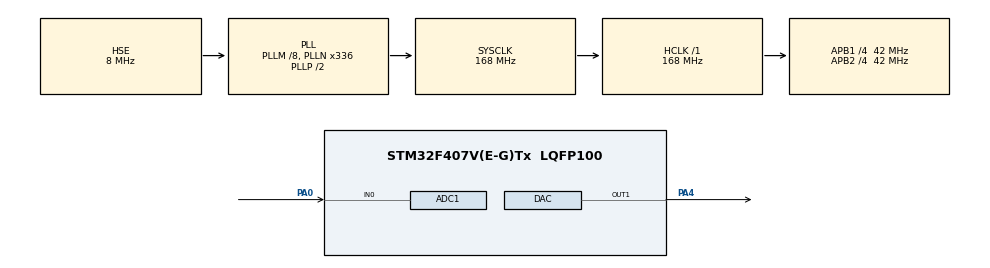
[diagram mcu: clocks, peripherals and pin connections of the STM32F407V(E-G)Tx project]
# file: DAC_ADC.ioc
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ADC1.Channel-0\#ChannelRegularConversion=ADC_CHANNEL_0
ADC1.ContinuousConvMode=ENABLE
ADC1.NbrOfConversionFlag=1
ADC1.Rank-0\#ChannelRegularConversion=1
ADC1.SamplingTime-0\#ChannelRegularConversion=ADC_SAMPLETIME_480CYCLES
ADC1.master=1
Mcu.Family=STM32F4
Mcu.Name=STM32F407V(E-G)Tx
Mcu.Package=LQFP100
NVIC.ADC_IRQn=true\:0\:0\:false\:false\:true
NVIC.PriorityGroup=NVIC_PRIORITYGROUP_4
PA0-WKUP.Signal=ADCx_IN0
PA4.Signal=COMP_DAC1_group
PH0-OSC_IN.Mode=HSE-External-Oscillator
PH0-OSC_IN.Signal=RCC_OSC_IN
PH1-OSC_OUT.Mode=HSE-External-Oscillator
PH1-OSC_OUT.Signal=RCC_OSC_OUT
ProjectManager.HeapSize=0x200
ProjectManager.StackSize=0x400
ProjectManager.TargetToolchain=MDK-ARM V5
RCC.48MHZClocksFreq_Value=84000000
RCC.AHBFreq_Value=168000000
RCC.APB1CLKDivider=RCC_HCLK_DIV4
RCC.APB1Freq_Value=42000000
RCC.APB1TimFreq_Value=84000000
RCC.APB2CLKDivider=RCC_HCLK_DIV4
RCC.APB2Freq_Value=42000000
RCC.APB2TimFreq_Value=84000000
RCC.CortexFreq_Value=168000000
RCC.HCLKFreq_Value=168000000
RCC.HSE_VALUE=8000000
RCC.HSI_VALUE=16000000
RCC.LSE_VALUE=32768
RCC.PLLM=8
RCC.PLLN=336
RCC.PLLSourceVirtual=RCC_PLLSOURCE_HSE
RCC.SYSCLKFreq_VALUE=168000000
RCC.SYSCLKSource=RCC_SYSCLKSOURCE_PLLCLK
RCC.VCOOutputFreq_Value=336000000
SH.ADCx_IN0.0=ADC1_IN0,IN0
SH.COMP_DAC1_group.0=DAC_OUT1,DAC_OUT1
board=DAC_ADC

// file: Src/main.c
/**
  ******************************************************************************
  * File Name          : main.c
  * Description        : Main program body
  ******************************************************************************
  *
  * COPYRIGHT(c) 2016 STMicroelectronics
  *
  * Redistribution and use in source and binary forms, with or without modification,
  * are permitted provided that the following conditions are met:
  *   1. Redistributions of source code must retain the above copyright notice,
  *      this list of conditions and the following disclaimer.
  *   2. Redistributions in binary form must reproduce the above copyright notice,
  *      this list of conditions and the following disclaimer in the documentation
  *      and/or other materials provided with the distribution.
  *   3. Neither the name of STMicroelectronics nor the names of its contributors
  *      may be used to endorse or promote products derived from this software
  *      without specific prior written permission.
  *
  * THIS SOFTWARE IS PROVIDED BY THE COPYRIGHT HOLDERS AND CONTRIBUTORS "AS IS"
  * AND ANY EXPRESS OR IMPLIED WARRANTIES, INCLUDING, BUT NOT LIMITED TO, THE
  * IMPLIED WARRANTIES OF MERCHANTABILITY AND FITNESS FOR A PARTICULAR PURPOSE ARE
  * DISCLAIMED. IN NO EVENT SHALL THE COPYRIGHT HOLDER OR CONTRIBUTORS BE LIABLE
  * FOR ANY DIRECT, INDIRECT, INCIDENTAL, SPECIAL, EXEMPLARY, OR CONSEQUENTIAL
  * DAMAGES (INCLUDING, BUT NOT LIMITED TO, PROCUREMENT OF SUBSTITUTE GOODS OR
  * SERVICES; LOSS OF USE, DATA, OR PROFITS; OR BUSINESS INTERRUPTION) HOWEVER
  * CAUSED AND ON ANY THEORY OF LIABILITY, WHETHER IN CONTRACT, STRICT LIABILITY,
  * OR TORT (INCLUDING NEGLIGENCE OR OTHERWISE) ARISING IN ANY WAY OUT OF THE USE
  * OF THIS SOFTWARE, EVEN IF ADVISED OF THE POSSIBILITY OF SUCH DAMAGE.
  *
  ******************************************************************************
  */
#include "stm32f4xx_hal.h"

/* USER CODE BEGIN Includes */

/* Mo ta hoat dong:
 * Chuong trinh thuc hien xuat ra gia tri dien ap tuong tu (DAC)tren chan PA4
 * Sau khoang thoi gian la 2S thi gia tri dien ap tang them 0.2V.
 * Sau do chuong trinh se thuc hien qua trinh chuyen doi tuong tu so (ADC) tren
 * chan PA0 va tinh toan gia tri dien ap. De kiem tra xem qua trinh DAC co dung
 * nhu mong muon khong, thi ta se noi day cha PA0 va chan PA4 .
 *
 * Ket noi phan cung:
 * Chan PA0 noi voi chan PA4
 */

/* USER CODE END Includes */

ADC_HandleTypeDef hadc1;

DAC_HandleTypeDef hdac;

/* USER CODE BEGIN PV */
/* Private variables ---------------------------------------------------------*/
uint16_t adc_value;
float theory_voltage=0,real_voltage=0;
/* USER CODE END PV */

void SystemClock_Config(void);
void Error_Handler(void);
static void MX_GPIO_Init(void);
static void MX_ADC1_Init(void);
static void MX_DAC_Init(void);

/* USER CODE BEGIN PFP */
/* Private function prototypes -----------------------------------------------*/

/* USER CODE END PFP */

int main(void)
{

  /* MCU Configuration----------------------------------------------------------*/

  /* Reset of all peripherals, Initializes the Flash interface and the Systick. */
  HAL_Init();
  /* Configure the system clock */
  SystemClock_Config();

  /* Initialize all configured peripherals */
  MX_GPIO_Init();
  MX_ADC1_Init();
  MX_DAC_Init();

  /* USER CODE BEGIN 2 */
	HAL_ADC_Start_IT(&hadc1);
	HAL_DAC_Start(&hdac,DAC_CHANNEL_1);
  /* USER CODE END 2 */

  /* Infinite loop */
  while (1)
  {
  /* USER CODE BEGIN 3 */
		HAL_DAC_SetValue(&hdac,DAC_CHANNEL_1,DAC_ALIGN_12B_R,(uint32_t)((theory_voltage/(float)3.0)*(float)4095.0));

		HAL_Delay(2000);

		theory_voltage+=(float)0.20;
		if(theory_voltage>(float)3.1)
		{
			theory_voltage=0;
		}
  }
  /* USER CODE END 3 */

}

/** System Clock Configuration
*/
void SystemClock_Config(void)
{

  RCC_OscInitTypeDef RCC_OscInitStruct;
  RCC_ClkInitTypeDef RCC_ClkInitStruct;

  __HAL_RCC_PWR_CLK_ENABLE();

  __HAL_PWR_VOLTAGESCALING_CONFIG(PWR_REGULATOR_VOLTAGE_SCALE1);

  RCC_OscInitStruct.OscillatorType = RCC_OSCILLATORTYPE_HSE;
  RCC_OscInitStruct.HSEState = RCC_HSE_ON;
  RCC_OscInitStruct.PLL.PLLState = RCC_PLL_ON;
  RCC_OscInitStruct.PLL.PLLSource = RCC_PLLSOURCE_HSE;
  RCC_OscInitStruct.PLL.PLLM = 8;
  RCC_OscInitStruct.PLL.PLLN = 336;
  RCC_OscInitStruct.PLL.PLLP = RCC_PLLP_DIV2;
  RCC_OscInitStruct.PLL.PLLQ = 4;
  if (HAL_RCC_OscConfig(&RCC_OscInitStruct) != HAL_OK)
  {
    Error_Handler();
  }

  RCC_ClkInitStruct.ClockType = RCC_CLOCKTYPE_HCLK|RCC_CLOCKTYPE_SYSCLK
                              |RCC_CLOCKTYPE_PCLK1|RCC_CLOCKTYPE_PCLK2;
  RCC_ClkInitStruct.SYSCLKSource = RCC_SYSCLKSOURCE_PLLCLK;
  RCC_ClkInitStruct.AHBCLKDivider = RCC_SYSCLK_DIV1;
  RCC_ClkInitStruct.APB1CLKDivider = RCC_HCLK_DIV4;
  RCC_ClkInitStruct.APB2CLKDivider = RCC_HCLK_DIV4;
  if (HAL_RCC_ClockConfig(&RCC_ClkInitStruct, FLASH_LATENCY_5) != HAL_OK)
  {
    Error_Handler();
  }

  HAL_SYSTICK_Config(HAL_RCC_GetHCLKFreq()/1000);

  HAL_SYSTICK_CLKSourceConfig(SYSTICK_CLKSOURCE_HCLK);

  /* SysTick_IRQn interrupt configuration */
  HAL_NVIC_SetPriority(SysTick_IRQn, 0, 0);
}

/* ADC1 init function */
static void MX_ADC1_Init(void)
{

  ADC_ChannelConfTypeDef sConfig;

    /**Configure the global features of the ADC (Clock, Resolution, Data Alignment and number of conversion)
    */
  hadc1.Instance = ADC1;
  hadc1.Init.ClockPrescaler = ADC_CLOCK_SYNC_PCLK_DIV2;
  hadc1.Init.Resolution = ADC_RESOLUTION_12B;
  hadc1.Init.ScanConvMode = DISABLE;
  hadc1.Init.ContinuousConvMode = ENABLE;
  hadc1.Init.DiscontinuousConvMode = DISABLE;
  hadc1.Init.ExternalTrigConvEdge = ADC_EXTERNALTRIGCONVEDGE_NONE;
  hadc1.Init.DataAlign = ADC_DATAALIGN_RIGHT;
  hadc1.Init.NbrOfConversion = 1;
  hadc1.Init.DMAContinuousRequests = DISABLE;
  hadc1.Init.EOCSelection = ADC_EOC_SINGLE_CONV;
  if (HAL_ADC_Init(&hadc1) != HAL_OK)
  {
    Error_Handler();
  }

    /**Configure for the selected ADC regular channel its corresponding rank in the sequencer and its sample time.
    */
  sConfig.Channel = ADC_CHANNEL_0;
  sConfig.Rank = 1;
  sConfig.SamplingTime = ADC_SAMPLETIME_480CYCLES;
  if (HAL_ADC_ConfigChannel(&hadc1, &sConfig) != HAL_OK)
  {
    Error_Handler();
  }

}

/* DAC init function */
static void MX_DAC_Init(void)
{

  DAC_ChannelConfTypeDef sConfig;

    /**DAC Initialization
    */
  hdac.Instance = DAC;
  if (HAL_DAC_Init(&hdac) != HAL_OK)
  {
    Error_Handler();
  }

    /**DAC channel OUT1 config
    */
  sConfig.DAC_Trigger = DAC_TRIGGER_NONE;
  sConfig.DAC_OutputBuffer = DAC_OUTPUTBUFFER_ENABLE;
  if (HAL_DAC_ConfigChannel(&hdac, &sConfig, DAC_CHANNEL_1) != HAL_OK)
  {
    Error_Handler();
  }

}

/** Configure pins as
        * Analog
        * Input
        * Output
        * EVENT_OUT
        * EXTI
*/
static void MX_GPIO_Init(void)
{

  /* GPIO Ports Clock Enable */
  __HAL_RCC_GPIOH_CLK_ENABLE();
  __HAL_RCC_GPIOA_CLK_ENABLE();

}

/* USER CODE BEGIN 4 */
void HAL_ADC_ConvCpltCallback(ADC_HandleTypeDef* hadc)
{
	if(hadc->Instance==hadc1.Instance)
	{
		adc_value=HAL_ADC_GetValue(&hadc1);
		real_voltage=(adc_value/4095.0)*3.0;
	}
}
/* USER CODE END 4 */

void Error_Handler(void)
{
  while(1)
  {
  }
}

/************************ (C) COPYRIGHT STMicroelectronics *****END OF FILE****/
